# LargeDummyDevice register map
File version: 1.0
Registers are 32-bit, read-write, no defined reset value unless marked. A register's access mark holds for its fields unless they carry their own. Offsets are from the block's base; [hi:lo] are bit positions.

## PERIPHERAL_3
Base 0x40002000
0x04 REG_1 — Register 1
  [18:17] FIELD_1
0x08 REG_2 — Register 2
  [28:25] FIELD_3, [23:19] FIELD_6, [22:18] FIELD_5, [20:16] FIELD_2, [12:11] FIELD_7, [14:10] FIELD_9, [11:7] FIELD_4, [8:4] FIELD_8, [2:0] FIELD_1
0x0C REG_3 — Register 3
  [34:31] FIELD_5, [32:31] FIELD_8, [32:29] FIELD_25, [29] FIELD_27, [28] FIELD_7, [27] FIELD_6, [26:25] FIELD_15, [27:25] FIELD_20, [27:23] FIELD_16, [23:22] FIELD_30, [21:20] FIELD_4, [23:19] FIELD_2, [19:17] FIELD_18, [19:17] FIELD_24, [18:16] FIELD_28, [19:15] FIELD_11, [13] FIELD_26, [16:12] FIELD_10, [15:12] FIELD_12, [14:12] FIELD_21, [12:11] FIELD_13, [10:9] FIELD_3, [7] FIELD_22, [8:6] FIELD_14, [6:4] FIELD_23, [5:3] FIELD_29, [3:0] FIELD_1, [2:0] FIELD_9, [4:0] FIELD_17, [4:0] FIELD_19
0x10 REG_4 — Register 4
  [34:30] FIELD_5, [29:27] FIELD_6, [27:26] FIELD_10, [24:23] FIELD_4, [25:22] FIELD_9, [21] FIELD_12, [21:20] FIELD_14, [21:20] FIELD_15, [19] FIELD_13, [20:17] FIELD_16, [18:16] FIELD_7, [17:13] FIELD_8, [14:11] FIELD_1, [12:10] FIELD_2, [9:8] FIELD_3, [4:0] FIELD_11
0x14 REG_5 — Register 5
  [15:14] FIELD_3, [16:13] FIELD_2, [5] FIELD_1
0x18 REG_6 — Register 6
  [33:30] FIELD_6, [31:29] FIELD_8, [29:26] FIELD_3, [27:24] FIELD_5, [24:23] FIELD_2, [21:19] FIELD_1, [19:15] FIELD_11, [11] FIELD_9, [12:10] FIELD_10, [11:9] FIELD_15, [12:8] FIELD_13, [8:6] FIELD_4, [4:3] FIELD_12, [5:1] FIELD_14, [0] FIELD_7
0x1C REG_7 — Register 7
  [31:29] FIELD_7, [27:26] FIELD_14, [26:25] FIELD_11, [25:24] FIELD_12, [23] FIELD_5, [26:22] FIELD_2, [25:22] FIELD_15, [23:21] FIELD_6, [22:20] FIELD_10, [12] FIELD_4, [14:11] FIELD_16, [13:9] FIELD_9, [10:8] FIELD_3, [8] FIELD_8, [10:8] FIELD_17, [7:4] FIELD_13, [6:3] FIELD_1
0x20 REG_8 — Register 8
  [30:29] FIELD_4, [28] FIELD_1, [26:24] FIELD_6, [26:24] FIELD_21, [25:22] FIELD_10, [21:19] FIELD_3, [17:14] FIELD_17, [15:12] FIELD_7, [15:12] FIELD_8, [16:12] FIELD_14, [12:10] FIELD_11, [9:8] FIELD_20, [10:7] FIELD_5, [9:6] FIELD_18, [7:5] FIELD_13, [6:5] FIELD_19, [7:4] FIELD_2, [7:3] FIELD_15, [5:2] FIELD_16, [2:1] FIELD_9, [3:1] FIELD_12
0x24 REG_9 — Register 9
  [34:30] FIELD_3, [28:27] FIELD_4, [19:17] FIELD_5, [11:9] FIELD_1, [10:9] FIELD_2
0x28 REG_10 — Register 10
  [33:30] FIELD_1, [28:27] FIELD_8, [30:27] FIELD_12, [26:24] FIELD_10, [25:23] FIELD_7, [22:20] FIELD_4, [22:19] FIELD_9, [19:17] FIELD_3, [16:14] FIELD_13, [14:12] FIELD_6, [9] FIELD_2, [13:9] FIELD_11, [3] FIELD_5
0x2C REG_11 — Register 11
  [25:23] FIELD_2, [24:22] FIELD_3, [22:21] FIELD_5, [18] FIELD_7, [18:15] FIELD_1, [15:13] FIELD_6, [13:12] FIELD_9, [8:6] FIELD_4, [7:5] FIELD_8
0x30 REG_12 — Register 12
  [31:29] FIELD_11, [29:27] FIELD_4, [25:23] FIELD_7, [19:18] FIELD_2, [18:15] FIELD_1, [19:15] FIELD_12, [13] FIELD_3, [12:11] FIELD_10, [15:11] FIELD_14, [9:8] FIELD_9, [6] FIELD_8, [9:5] FIELD_6, [6:3] FIELD_5, [5:3] FIELD_13
0x34 REG_13 — Register 13
  [35:31] FIELD_8, [30:29] FIELD_1, [30:28] FIELD_5, [29:26] FIELD_6, [30:26] FIELD_20, [26:25] FIELD_11, [27:24] FIELD_15, [27:24] FIELD_18, [27:23] FIELD_13, [22:18] FIELD_16, [19:17] FIELD_9, [19:15] FIELD_2, [16:15] FIELD_17, [14] FIELD_10, [17:13] FIELD_3, [12:10] FIELD_7, [11:10] FIELD_19, [11:7] FIELD_4, [4:2] FIELD_14, [1] FIELD_12
0x38 REG_14 — Register 14
  [34:31] FIELD_15, [27] FIELD_10, [26:24] FIELD_5, [23:22] FIELD_1, [22] FIELD_2, [23:21] FIELD_19, [19] FIELD_7, [17] FIELD_21, [18:15] FIELD_17, [18:14] FIELD_8, [14] FIELD_9, [17:14] FIELD_20, [15:13] FIELD_3, [12:10] FIELD_14, [12:10] FIELD_18, [12:9] FIELD_4, [10:9] FIELD_16, [7] FIELD_11, [10:6] FIELD_13, [7:4] FIELD_12, [2] FIELD_6
0x3C REG_15 — Register 15
  [31:27] FIELD_5, [20:19] FIELD_3, [12:8] FIELD_6, [6] FIELD_4, [8:5] FIELD_2, [1] FIELD_1
0x40 REG_16 — Register 16
  [31] FIELD_2, [19:17] FIELD_1, [14] FIELD_6, [10] FIELD_3, [12:10] FIELD_4, [8:4] FIELD_7, [4:0] FIELD_5
0x44 REG_17 — Register 17
  [33:31] FIELD_11, [35:31] FIELD_19, [31] FIELD_30, [31:30] FIELD_24, [31:29] FIELD_3, [32:29] FIELD_23, [29:26] FIELD_21, [27:24] FIELD_14, [22:21] FIELD_22, [25:21] FIELD_27, [24:20] FIELD_2, [23:20] FIELD_17, [22:19] FIELD_16, [23:19] FIELD_28, [22:18] FIELD_18, [18:17] FIELD_29, [16] FIELD_6, [14] FIELD_13, [13:12] FIELD_10, [13:12] FIELD_26, [10] FIELD_8, [11:9] FIELD_1, [9] FIELD_9, [8:7] FIELD_15, [9:6] FIELD_4, [10:6] FIELD_7, [8:4] FIELD_5, [5:3] FIELD_20, [3] FIELD_25, [6:2] FIELD_12
0x48 REG_18 — Register 18
  [34:30] FIELD_17, [31:29] FIELD_19, [25] FIELD_11, [24:23] FIELD_9, [24:20] FIELD_10, [19] FIELD_1, [17] FIELD_13, [16:15] FIELD_8, [16:14] FIELD_15, [16:13] FIELD_18, [12:11] FIELD_7, [13:11] FIELD_20, [12:10] FIELD_4, [11:10] FIELD_12, [8] FIELD_5, [7:5] FIELD_2, [5:4] FIELD_3, [2] FIELD_6, [4:1] FIELD_14, [0] FIELD_16
0x4C REG_19 — Register 19
  [31] FIELD_7, [31:30] FIELD_4, [26:24] FIELD_6, [10:7] FIELD_5, [3] FIELD_8, [6:2] FIELD_2, [3:1] FIELD_1, [3:1] FIELD_3
0x50 REG_20 — Register 20
  [33:30] FIELD_20, [30:29] FIELD_6, [30:29] FIELD_7, [30:28] FIELD_21, [25:23] FIELD_2, [26:23] FIELD_24, [23:22] FIELD_3, [21] FIELD_12, [23:21] FIELD_25, [20:18] FIELD_8, [21:17] FIELD_15, [16] FIELD_16, [16:14] FIELD_4, [15:13] FIELD_5, [14:13] FIELD_23, [14:12] FIELD_11, [12:10] FIELD_9, [14:10] FIELD_13, [7:6] FIELD_22, [8:4] FIELD_14, [3] FIELD_1, [7:3] FIELD_17, [5:3] FIELD_18, [4:2] FIELD_19, [1:0] FIELD_10
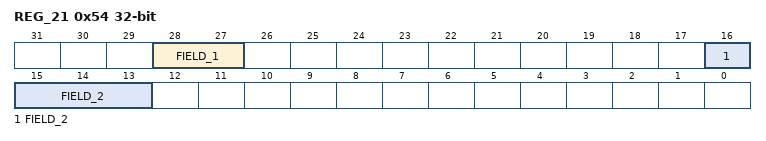
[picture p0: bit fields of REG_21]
0x54 REG_21 — Register 21
  [28:27] FIELD_1, [16:13] FIELD_2
0x58 REG_22 — Register 22
  [32:31] FIELD_1, [30] FIELD_8, [32:30] FIELD_14, [30:29] FIELD_7, [30:28] FIELD_2, [29:28] FIELD_29, [28:27] FIELD_5, [29:27] FIELD_11, [26] FIELD_16, [25:24] FIELD_18, [26:23] FIELD_28, [23:22] FIELD_13, [25:21] FIELD_6, [22:20] FIELD_10, [23:19] FIELD_9, [21:18] FIELD_3, [17] FIELD_15, [19:17] FIELD_25, [18:17] FIELD_26, [17:16] FIELD_21, [19:15] FIELD_19, [16:15] FIELD_20, [17:13] FIELD_30, [11] FIELD_17, [13:10] FIELD_24, [8:7] FIELD_22, [6:5] FIELD_4, [7:5] FIELD_23, [5] FIELD_32, [7:4] FIELD_31, [6:3] FIELD_12, [4:1] FIELD_27
0x5C REG_23 — Register 23
  [32:28] FIELD_6, [29:28] FIELD_8, [26] FIELD_4, [25:21] FIELD_7, [14:13] FIELD_3, [9:8] FIELD_2, [7:5] FIELD_9, [6:2] FIELD_5, [1] FIELD_1
0x60 REG_24 — Register 24
  [32:28] FIELD_13, [28:27] FIELD_2, [28:26] FIELD_15, [26:25] FIELD_5, [27:24] FIELD_7, [20:19] FIELD_11, [22:18] FIELD_12, [19:17] FIELD_9, [16] FIELD_3, [19:16] FIELD_14, [13] FIELD_4, [11:7] FIELD_10, [9:5] FIELD_1, [7:3] FIELD_8, [4:1] FIELD_6
0x64 REG_25 — Register 25
  [27] FIELD_4, [31:27] FIELD_6, [27:26] FIELD_9, [28:25] FIELD_5, [26:24] FIELD_7, [22:20] FIELD_3, [21:19] FIELD_10, [20:17] FIELD_2, [19:17] FIELD_8, [11:10] FIELD_1, [13:10] FIELD_11, [8:4] FIELD_12
0x68 REG_26 — Register 26
  [4:1] FIELD_1
0x6C REG_27 — Register 27
  [34:31] FIELD_2, [18] FIELD_3, [17:15] FIELD_1
0x70 REG_28 — Register 28
  [34:31] FIELD_1, [34:31] FIELD_15, [28:24] FIELD_17, [27:23] FIELD_13, [22:21] FIELD_10, [19] FIELD_2, [23:19] FIELD_6, [20:18] FIELD_4, [20:17] FIELD_14, [20:17] FIELD_16, [18:16] FIELD_3, [13:9] FIELD_7, [10:7] FIELD_11, [9:6] FIELD_18, [4] FIELD_8, [6:4] FIELD_12, [0] FIELD_5, [1:0] FIELD_9
0x74 REG_29 — Register 29
  [34:30] FIELD_7, [33:30] FIELD_19, [29:26] FIELD_13, [29:26] FIELD_16, [27:23] FIELD_15, [23:22] FIELD_14, [22:21] FIELD_4, [25:21] FIELD_10, [24:20] FIELD_11, [20:18] FIELD_5, [16:15] FIELD_6, [10] FIELD_8, [10] FIELD_12, [13:9] FIELD_9, [10:7] FIELD_20, [5:4] FIELD_17, [4:3] FIELD_2, [2:1] FIELD_3, [3:0] FIELD_1, [1:0] FIELD_18
0x78 REG_30 — Register 30
  [35:31] FIELD_1, [33:30] FIELD_16, [32:30] FIELD_25, [33:29] FIELD_15, [32:28] FIELD_9, [29:27] FIELD_11, [23] FIELD_28, [24:22] FIELD_4, [25:22] FIELD_5, [25:22] FIELD_6, [22:21] FIELD_2, [21] FIELD_19, [23:21] FIELD_27, [24:20] FIELD_20, [22:18] FIELD_21, [22:18] FIELD_23, [20:18] FIELD_30, [19:17] FIELD_26, [15] FIELD_7, [14:13] FIELD_13, [13:10] FIELD_8, [12:8] FIELD_10, [9:8] FIELD_17, [8] FIELD_18, [11:8] FIELD_24, [11:7] FIELD_3, [4] FIELD_31, [4:3] FIELD_12, [3] FIELD_14, [3:2] FIELD_22, [1] FIELD_29
0x7C REG_31 — Register 31
  [34:30] FIELD_18, [31:29] FIELD_20, [29:27] FIELD_6, [28:27] FIELD_17, [29:26] FIELD_3, [28:25] FIELD_19, [25:24] FIELD_25, [22] FIELD_2, [22] FIELD_23, [24:21] FIELD_1, [24:21] FIELD_21, [24:21] FIELD_24, [24:20] FIELD_26, [22:19] FIELD_10, [18] FIELD_4, [16:15] FIELD_9, [15] FIELD_13, [15:13] FIELD_16, [12:11] FIELD_5, [14:11] FIELD_22, [6:5] FIELD_15, [4:3] FIELD_7, [7:3] FIELD_8, [7:3] FIELD_12, [6:3] FIELD_14, [4:1] FIELD_11
0x80 REG_32 — Register 32
  [31] FIELD_20, [30] FIELD_24, [32:28] FIELD_5, [31:28] FIELD_17, [29:28] FIELD_25, [27:26] FIELD_13, [27:25] FIELD_16, [29:25] FIELD_18, [26:24] FIELD_3, [25:23] FIELD_1, [26:23] FIELD_4, [21] FIELD_6, [22:21] FIELD_14, [22:21] FIELD_22, [20:18] FIELD_7, [19:17] FIELD_21, [17:16] FIELD_19, [15] FIELD_15, [16:12] FIELD_11, [11] FIELD_27, [7] FIELD_29, [8:6] FIELD_9, [6:5] FIELD_10, [2:1] FIELD_2, [1] FIELD_12, [5:1] FIELD_26, [2:1] FIELD_28, [3:0] FIELD_8, [0] FIELD_23
0x84 REG_33 — Register 33
  [31] FIELD_6, [29:28] FIELD_1, [30:28] FIELD_12, [26:25] FIELD_11, [21] FIELD_5, [23:19] FIELD_9, [17] FIELD_13, [16] FIELD_14, [19:15] FIELD_3, [10:9] FIELD_8, [6:4] FIELD_2, [6:4] FIELD_7, [7:3] FIELD_4, [4:2] FIELD_10
0x88 REG_34 — Register 34
  [31] FIELD_6, [32:29] FIELD_1, [29:28] FIELD_3, [29:28] FIELD_11, [31:27] FIELD_15, [25] FIELD_7, [24] FIELD_4, [26:22] FIELD_2, [16] FIELD_17, [18:15] FIELD_8, [18:14] FIELD_5, [13:12] FIELD_14, [14:11] FIELD_10, [11:8] FIELD_12, [6] FIELD_13, [4:2] FIELD_16, [4:1] FIELD_9
0x8C REG_35 — Register 35
  [17:16] FIELD_5, [19:15] FIELD_1, [15] FIELD_2, [14] FIELD_4, [11:9] FIELD_3
0x90 REG_36 — Register 36
  [33:30] FIELD_20, [29] FIELD_15, [32:28] FIELD_23, [31:27] FIELD_18, [30:26] FIELD_11, [29:25] FIELD_5, [26:24] FIELD_21, [25:24] FIELD_26, [22] FIELD_28, [20] FIELD_13, [22:19] FIELD_27, [22:18] FIELD_6, [21:17] FIELD_4, [17:15] FIELD_8, [17:14] FIELD_1, [10] FIELD_10, [12:10] FIELD_12, [11:10] FIELD_14, [11:9] FIELD_9, [12:8] FIELD_22, [6:5] FIELD_2, [8:5] FIELD_7, [5] FIELD_17, [4:3] FIELD_19, [2] FIELD_24, [3:2] FIELD_25, [1] FIELD_3, [3:1] FIELD_16
0x94 REG_37 — Register 37
  [23:22] FIELD_2, [21:17] FIELD_5, [15:14] FIELD_3, [12:9] FIELD_1, [9:7] FIELD_4
0x98 REG_38 — Register 38
  [31] FIELD_7, [35:31] FIELD_29, [31:30] FIELD_10, [29] FIELD_1, [30:26] FIELD_15, [27:26] FIELD_17, [27:26] FIELD_27, [25:24] FIELD_22, [24] FIELD_24, [26:22] FIELD_3, [24:22] FIELD_13, [22:20] FIELD_20, [23:19] FIELD_14, [19] FIELD_26, [18] FIELD_28, [20:16] FIELD_8, [17:15] FIELD_12, [16:14] FIELD_21, [12:11] FIELD_6, [15:11] FIELD_25, [13:10] FIELD_11, [10:8] FIELD_23, [11:7] FIELD_4, [11:7] FIELD_18, [9:6] FIELD_5, [8:5] FIELD_16, [6:5] FIELD_19, [7:3] FIELD_30, [3] FIELD_31, [5:1] FIELD_2, [2:0] FIELD_9
0x9C REG_39 — Register 39
  [29:28] FIELD_9, [31:27] FIELD_7, [21] FIELD_11, [22:20] FIELD_5, [24:20] FIELD_6, [15] FIELD_1, [13] FIELD_2, [15:12] FIELD_10, [10] FIELD_4, [9:7] FIELD_13, [7:6] FIELD_12, [6:5] FIELD_8, [5:2] FIELD_3
0xA0 REG_40 — Register 40
  [20:19] FIELD_1
0xA4 REG_41 — Register 41
  [31:30] FIELD_26, [29:27] FIELD_5, [29:27] FIELD_18, [30:26] FIELD_4, [26] FIELD_7, [24] FIELD_19, [25:23] FIELD_24, [25:22] FIELD_13, [26:22] FIELD_15, [21] FIELD_25, [24:20] FIELD_2, [22:20] FIELD_11, [19] FIELD_22, [21:18] FIELD_1, [19:17] FIELD_12, [14:12] FIELD_6, [16:12] FIELD_10, [13:12] FIELD_20, [12] FIELD_27, [14:12] FIELD_28, [12:10] FIELD_9, [12:10] FIELD_16, [10:7] FIELD_17, [11:7] FIELD_21, [5:2] FIELD_8, [4:1] FIELD_14, [3:0] FIELD_3, [3:0] FIELD_23
